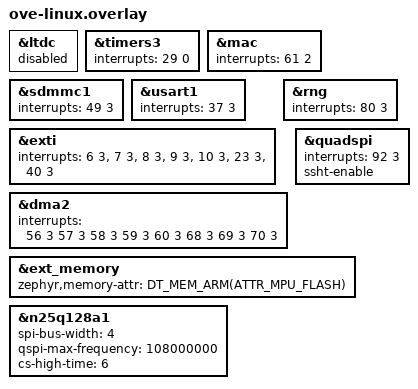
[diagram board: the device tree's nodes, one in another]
/*
 * Copyright (C) 2026 Kamil Lulko <kamil.lulko@gmail.com>
 *
 * SPDX-License-Identifier: GPL-3.0-or-later
 *
 * Linux personality (headless) on the STM32F746G-Discovery. The upstream board enables the LTDC
 * display, which uses the 8 MB FMC SDRAM (sdram1 @0xC0000000) as its framebuffer. The Linux
 * personality places its program-image pool (NREG x 768K) in that same SDRAM (the "SDRAM1" NOLOAD
 * linker region, via Z_GENERIC_SECTION in backends/zephyr/zephyr_lxp_host.c), so disable the display
 * to free the whole region. The FMC controller itself stays enabled (the memc driver still brings
 * the SDRAM up at boot).
 */

&ltdc {
	status = "disabled";
};

/* Interrupt-priority contract for the personality workload. Zephyr priority 0
 * is the highest ordinary (kernel-callable) level and belongs to the TIM3
 * scope deadline. Storage, network, and board peripherals remain
 * kernel-callable but cannot delay that reference ISR. The display priority
 * is applied in ove-linux-fb.overlay, where that device is re-enabled. */
&timers3 {
	interrupts = <29 0>;
};

&mac {
	interrupts = <61 2>;
};

&sdmmc1 {
	interrupts = <49 3>;
};

&usart1 {
	interrupts = <37 3>;
};

&exti {
	interrupts = <6 3>, <7 3>, <8 3>, <9 3>, <10 3>, <23 3>, <40 3>;
};

/* AT_RANDOM/getrandom use Zephyr's fail-closed CSPRNG path backed by the
 * STM32F7 hardware entropy peripheral. Keep it below the scope deadline IRQ. */
&rng {
	interrupts = <80 3>;
	status = "okay";
};

&dma2 {
	interrupts = <56 3 57 3 58 3 59 3 60 3 68 3 69 3 70 3>;
};

/*
 * Free an MPU region for the program's memory domain. This M7 has only 8 PMSAv7 regions; the Linux
 * program needs three domain partitions (libc TLS + image + dynamic arena) plus its K_USER stack.
 * The STM32 seam deliberately omits Zephyr's unused malloc partition. These do not fit alongside
 * the full static set and stack guard. Delete the board's placeholder QSPI memory-region because
 * it duplicates &ext_memory below; the rootfs still needs one static RO+X mapping at 0x90000000.
 */
/delete-node/ &quadspi_memory;

&quadspi {
	status = "okay";
	interrupts = <92 3>;
	/* Enable the QUADSPI half-cycle Sample Shift (SampleShifting = HALFCYCLE), matching the
	 * STM32Cube/FreeRTOS BSP + the NuttX board patch. The stock Zephyr driver leaves it NONE
	 * unless ssht-enable is set; without it memory-mapped quad reads are marginal at 108 MHz. */
	ssht-enable;
};

/*
 * Rootfs and guest-text XIP window. Every STM32 Linux-personality profile uses the QSPI NOR,
 * including headless Minimal. Retype the board's existing static region to Normal, user RO+X;
 * deleting &quadspi_memory above avoids consuming a second PMSAv7 MPU region for the same range.
 */
&ext_memory {
	zephyr,memory-attr = <DT_MEM_ARM(ATTR_MPU_FLASH)>;
};

/* Fast 1-4-4 memory-mapped reads at the N25Q128A's rated quad ceiling. Match
 * the STM32746G BSP and NuttX seam's six-cycle chip-select-high interval: the
 * upstream Zephyr board value is only four cycles, which is marginal at
 * 108 MHz under sustained XIP plus peripheral traffic. */
&n25q128a1 {
	spi-bus-width = <4>;
	qspi-max-frequency = <108000000>;
	cs-high-time = <6>;
};
